# nrf9230_application register map
Vendor: Nordic Semiconductor; Series: nRF92; File version: 1
CPU: CM33 r0p4, little endian, MPU, FPU, 3 interrupt priority bits, 480 interrupts, 8 SAU regions
Registers are 32-bit, read-write, reset 0x0 unless marked. A register's access mark holds for its fields unless they carry their own. Offsets are from the block's base; [hi:lo] are bit positions; lines under a group give offsets from that group; {n}, {i} and the like mark numbered series.

## GLOBAL_FICR_NS — Factory Information Configuration Registers
Base 0x0FFFE000
0x00 SOCINFO group — Unspecified
  0x00 PARTNO ro reset 0xFFFFFFFF — Part number.
    [31:0] PART
  0x04 HWREVISION ro reset 0xFFFFFFFF — Hardware revision.
    [31:0] HWREVISION — Hardvare revision.
  0x08 PRODUCTIONREVISION ro reset 0xFFFFFFFF — Production reversion.
0x0C BLE group — Unspecified
  0x00 ADDRTYPE ro reset 0xFFFFFFFF — Device address type.
    [0] TYPE
      0=Public address; 1=Random address
  {0x4+4j} ADDR[{j}] (j=0..1) ro reset 0xFFFFFFFF — Description collection: 48 bit device address.
    [31:0] ADDR — Device address [n].
  {0xC+4j} ER[{j}] (j=0..3) ro reset 0xFFFFFFFF — Description collection: Encryption Root.
    [31:0] ER — Encryption root word [n].
  {0x1C+4j} IR[{j}] (j=0..3) ro reset 0xFFFFFFFF — Description collection: Identity Root.
    [31:0] IR — Identity root word [n].
0x50 INFO group — Device info
  0x00 CONFIGID ro reset 0xFFFFFFFF — Configuration identifier
    [15:0] HWID — Identification number for the HW
  0x04 PART ro reset 0xFFFFFFFF — Part code
    [31:0] PART
      0xFFFFFFFF=Unspecified
  0x08 VARIANT ro reset 0xFFFFFFFF — Part Variant, Hardware version and Production configuration
    [31:0] VARIANT — Part Variant, Hardware version and Production configuration, encoded as ASCII
      0xFFFFFFFF=Unspecified
  0x0C PACKAGE ro reset 0xFFFFFFFF — Package option
    [31:0] PACKAGE
      0xFFFFFFFF=Unspecified
  0x10 RAM ro reset 0xFFFFFFFF — RAM variant
    [31:0] RAM
      0xFFFFFFFF=Unspecified
  0x14 MRAM ro reset 0xFFFFFFFF — MRAM variant
    [31:0] MRAM
      0xFFFFFFFF=Unspecified
  0x18 CODEPAGESIZE ro reset 0x1000 — Code memory page size in bytes
    [31:0] CODEPAGESIZE
      0xFFFFFFFF=Unspecified
  0x1C CODESIZE ro reset 0x100 — Code memory size
    [31:0] CODESIZE — Code memory size in number of pages
      0xFFFFFFFF=Unspecified
  0x20 DEVICETYPE ro
    [31:0] DEVICETYPE
      0=Die (Device is an physical DIE); 0xFFFFFFFF=FPGA (Device is an FPGA)
0x80 SIPINFO group — SIP-specific device info
  0x00 PARTNO ro reset 0xFFFFFFFF — SIP part number
  {0x4+j} HWREVISION[{j}] (j=0..3) 8-bit ro reset 0xFF — Description collection: SIP hardware revision, encoded in ASCII, ex B0A or B1A
    [7:0] HWREVISION
  {0x8+j} VARIANT[{j}] (j=0..3) 8-bit ro reset 0xFF — Description collection: SIP VARIANT, encoded in ASCII, ex SIAA, SIBA or SICA
    [7:0] VARIANT
  0x0C PMICVERSION ro
    [31:0] PMICVERSION — PMIC version, incremental code
  {0x10+j} TESTSITE[{j}] (j=0..3) 8-bit ro — Description collection: Test site, in ascii
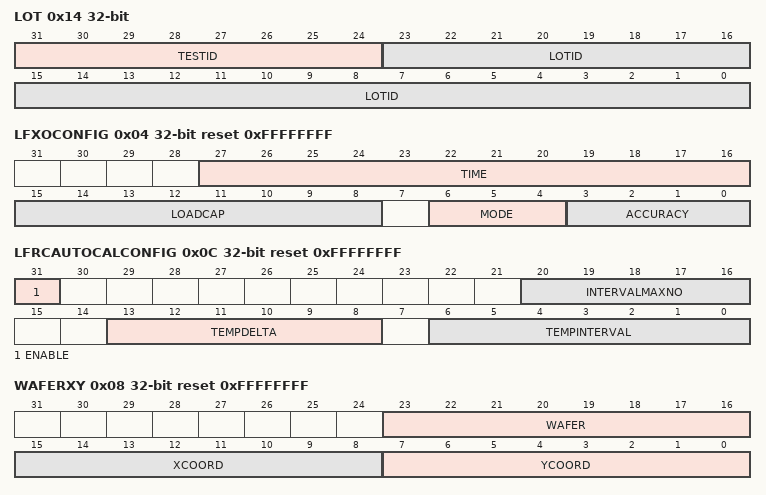
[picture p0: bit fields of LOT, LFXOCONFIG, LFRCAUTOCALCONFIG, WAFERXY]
  0x14 LOT ro — Lot number + test index in hex format (number digits 0-9).
    [31:24] TESTID — Test ID in hex format
    [23:0] LOTID — Lot number in hex format
  {0x18+j} TESTPROGRAMID[{j}] (j=0..3) 8-bit ro — Description collection: Test program id, in ascii
  0x1C OSATPARTNO ro reset 0xFFFFFFFF — OSAT part number
  {0x20+j} HWBUILDVERSION[{j}] (j=0..3) 8-bit ro reset 0xFF — Description collection: OSAT production build version
  0x24 OVERRIDE group — Unspecified
    0x00 LFOSC group — Unspecified
      0x00 CONFIG reset 0xFFFFFFFF — LF oscillator configuration. Note. This configuration overrides corresponding LF oscillator configuration in BICR when set.
        [3:0] SRC — LF oscillator source.
          15=Unconfigured (LF oscillator source is unconfigured. Default will be used.); 0=LFXO (Use LFXO as source for the LF oscillator.); 1=LFRC (Use LFRC as source for the LF oscillator.); 2=LFLPRC (Use LFLPRC as source for the LF oscillator.); 3=Synth (Use LF Synth as source for the LF oscillator.)
      0x04 LFXOCONFIG reset 0xFFFFFFFF — LFXO configuration. Note. This configuration overrides corresponding LFXO configuration in BICR when set.
        [27:16] TIME — LFXO startup time in ms.
          0xFFF=Unconfigured (Startup time has not been configured.)
        [15:8] LOADCAP — Built-in load capacitors selection in 1 pF steps. Max. value 25 pF.
          255=Unconfigured (The built-in load capacitors is unconfigured. LFXO will not start unless LOADCAP is configured.); 0=External (Do not use the built-in load capacitors, only external capacitors will be used.)
        [6:4] MODE — LFXO mode. LFXO will not start unless MODE is configured.
          7=Unconfigured (The mode is unconfigured.); 0=Pierce (LFXO Pierce mode.); 1=PIXO (LFXO PIXO mode.); 2=ExtSine (LFXO in external sine wave mode.); 3=ExtSquare (LFXO in external square wave mode.)
        [3:0] ACCURACY — LFXO crystal or external signal accuracy.
          15=Unconfigured (The accuracy is unconfigured.); 0=500ppm (LFXO crystal or external signal has an accuracy of 500 ppm.); 1=250ppm (LFXO crystal or external signal has an accuracy of 250 ppm.); 2=150ppm (LFXO crystal or external signal has an accuracy of 150 ppm.); 3=100ppm (LFXO crystal or external signal has an accuracy of 100 ppm.); 4=75ppm (LFXO crystal or external signal has an accuracy of 75 ppm.); 5=50ppm (LFXO crystal or external signal has an accuracy of 50 ppm.); 6=30ppm (LFXO crystal or external signal has an accuracy of 30 ppm.); 7=20ppm (LFXO crystal or external signal has an accuracy of 20 ppm.)
      0x08 LFXOCAL reset 0xFFFFFFFF — LFXO calibration needed. Must be written to 0xFFFFFFFF after any modification of the LFXO board circuit, load capacitance, or crystal swap. Note. This configuration overrides corresponding LFXO calibration in BICR when set.
        [31:0] LFXOCAL — LFXO calibration needed. Must be written to 0xFFFFFFFF after any modification of the LFXO board circuit, load capacitance, or crystal swap.
          0xFFFFFFFF=Calibrate the LFXO at startup
      0x0C LFRCAUTOCALCONFIG reset 0xFFFFFFFF — LFRC autocalibration configuration. Note. This configuration overrides corresponding LFRC autocalibration configuration in BICR when set.
        [31] ENABLE — LFRC.AUTOCALCONFIG register enable.
          0=Enabled (LFRC.AUTOCALCONFIG register has been configured and can be used.); 1=Disabled (LFRC.AUTOCALCONFIG register has not been configured and cannot be used.)
        [20:16] INTERVALMAXNO — Maximum number of TEMPINTERVAL periods in between calibrations, independent of temperature changes.
        [13:8] TEMPDELTA — Temperature delta that should trigger a calibration in 0.25 degrees steps.
        [6:0] TEMPINTERVAL — Temperature measurement interval in 0.25 s steps.
    0x10 HFXO64M group — Unspecified
      0x00 CONFIG reset 0xFFFFFFFF — HFXO64M configuration. Note. This configuration overrides corresponding XO configuration in BICR when set.
        [2:0] MODE — HFXO64M mode.
          7=Unconfigured (The mode is unconfigured.); 0=Normal operating mode; 1=TCXO (TCXO/bypass mode); {v}=Crystal{v} (Reserved value) (v=2..6)
      0x04 STARTUPTIME reset 0xFFFFFFFF — HFXO64M startup time in us. Note. This configuration overrides corresponding XO configuration in BICR when set.
        [31:0] TIME — HFXO64M startup time in us.
          0xFFFFFFFF=Unconfigured (Startup time has not been configured.)
0xC0 PRODTEST group — Unspecified
  0x00 CP group — Unspecified
    {0x0+4k} LOTNR[{k}] (k=0..1) ro reset 0xFFFFFFFF — Description collection: Lot number.
      [31:0] LOTNR — Lot number
    0x08 WAFERXY ro reset 0xFFFFFFFF — Wafer number and die X,Y coordinate.
      [23:16] WAFER — Wafer number
      [15:8] XCOORD — Die x coordinate
      [7:0] YCOORD — Die y coordinate
    0x0C PROGVERSION1 ro reset 0xFFFFFFFF — CP1 test program version.
      [31:0] VAL — CP1 test program version
    0x10 PROGVERSION2 ro reset 0xFFFFFFFF — CP2 test program version.
      [31:0] VAL — CP2 test program version
    0x14 PASSID1 ro reset 0xFFFFFFFF — CP1 pass ID.
      [31:0] VAL
    0x18 PASSID2 ro reset 0xFFFFFFFF — CP2 pass ID.
      [31:0] VAL
    0x1C TIMESTAMP1 ro reset 0xFFFFFFFF — Timestamp for when CP1 starts or ends (YYYYMMDDTHHMMSS)
      [31:0] VAL — CP1 timestamp
    0x20 TIMESTAMP2 ro reset 0xFFFFFFFF — Timestamp for when CP2 starts or ends (YYYYMMDDTHHMMSS)
      [31:0] VAL — CP2 timestamp
  0x24 FT group — Unspecified
    0x00 PROGVERSION1 ro reset 0xFFFFFFFF — FT1 test program version.
      [31:0] PROGVERSION1 — FT1 test program version
    0x04 PROGVERSION2 ro reset 0xFFFFFFFF — FT2/EQA test program version.
      [31:0] PROGVERSION2 — FT2/EQA test program version
    0x08 PASSID1 ro reset 0xFFFFFFFF — FT1 pass ID.
      [31:0] VAL
    0x0C PASSID2 ro reset 0xFFFFFFFF — FT2/EQA pass ID.
      [31:0] VAL
    0x10 TIMESTAMP1 ro reset 0xFFFFFFFF — Timestamp for when FT1 starts or ends (YYYYMMDDTHHMMSS)
      [31:0] VAL — FT1 timestamp
    0x14 TIMESTAMP2 ro reset 0xFFFFFFFF — Timestamp for when FT2/EQA starts or ends (YYYYMMDDTHHMMSS)
      [31:0] VAL — FT2/EQA timestamp
0x100 TRIM group — Unspecified
  0x00 SYSCTRL group — Unspecified
    0x00 FLL16M group — Unspecified
      0x00 CONFIG group — Unspecified
        0x00 CFGCKSW16M ro reset 0xFFFFFFFF — Config value for SYSCTRL.FLL16M.CONFIG.CFGCKSW16M
          [31:0] VALUE — Config value
      0x04 TRIM group — Unspecified
        0x00 RCOARSE ro reset 0xFFFFFFFF — Trim value for SYSCTRL.FLL16M.TRIM.RCOARSE
          [31:0] VALUE — Trim value
        0x04 RFINE ro reset 0xFFFFFFFF — Trim value for SYSCTRL.FLL16M.TRIM.RFINE
          [31:0] VALUE — Trim value
        0x08 VSUP ro reset 0xFFFFFFFF — Trim value for SYSCTRL.FLL16M.TRIM.VSUP
          [31:0] VALUE — Trim value
        0x0C CKSW16MTRIM ro reset 0xFFFFFFFF — Trim value for SYSCTRL.FLL16M.TRIM.CKSW16MTRIM
          [31:0] VALUE — Trim value
        0x10 TCOEF ro reset 0xFFFFFFFF — Trim value for SYSCTRL.FLL16M.TRIM.TCOEF
          [31:0] VALUE — Trim value
    0x18 LFRC group — Unspecified
      0x00 CAL group — Unspecified
        0x00 LFRCOSCTRIM ro reset 0xFFFFFFFF — Trim value for SYSCTRL.LFRC.CAL.LFRCOSCTRIM
          [31:0] VALUE — Trim value
    0x1C LFXO group — Unspecified
      0x00 TRIM group — Unspecified
        0x00 PDLOWERTHR ro reset 0xFFFFFFFF — Trim value for SYSCTRL.LFXO.TRIM.PDLOWERTHR
          [31:0] VALUE — Trim value
        0x04 PDUPPERTHR ro reset 0xFFFFFFFF — Trim value for SYSCTRL.LFXO.TRIM.PDUPPERTHR
          [31:0] VALUE — Trim value
        0x08 BIAS ro reset 0xFFFFFFFF — Trim value for SYSCTRL.LFXO.TRIM.BIAS
          [31:0] VALUE — Trim value
        0x0C PIXO ro reset 0xFFFFFFFF — Trim value for SYSCTRL.LFXO.TRIM.PIXO
          [31:0] VALUE — Trim value
        0x10 TRIMBUS ro reset 0xFFFFFFFF — Trim value for SYSCTRL.LFXO.TRIM.TRIMBUS
          [31:0] VALUE — Trim value
    0x30 HFXO64M group — Unspecified
      0x00 TRIM group — Unspecified
        0x00 DOUBLERCOMP ro reset 0xFFFFFFFF — Trim value for SYSCTRL.HFXO64M.TRIM.DOUBLERCOMP
          [31:0] VALUE — Trim value
        0x04 CHIRPTUNE ro reset 0xFFFFFFFF — Trim value for SYSCTRL.HFXO64M.TRIM.CHIRPTUNE
          [31:0] VALUE — Trim value
        0x08 RTUNE ro reset 0xFFFFFFFF — Trim value for SYSCTRL.HFXO64M.TRIM.RTUNE
          [31:0] VALUE — Trim value
    0x3C LFLPRC group — Unspecified
      0x00 VSUP ro reset 0xFFFFFFFF — Trim value for SYSCTRL.LFLPRC.TRIM.VSUP
        [31:0] VALUE — Trim value
      0x04 RCOARSE ro reset 0xFFFFFFFF — Trim value for SYSCTRL.LFLPRC.TRIM.RCOARSE
        [31:0] VALUE — Trim value
      0x08 RFINE ro reset 0xFFFFFFFF — Trim value for SYSCTRL.LFLPRC.TRIM.RFINE
        [31:0] VALUE — Trim value
      0x0C PWMFINE ro reset 0xFFFFFFFF — Trim value for SYSCTRL.LFLPRC.TRIM.PWMFINE
        [31:0] VALUE — Trim value
    0x74 AUDIOPLL group — Unspecified
      0x00 TRIM group — Unspecified
        0x00 CTUNE ro reset 0xFFFFFFFF — Trim value for SYSCTRL.AUDIOPLL.TRIM.CTUNE
          [31:0] VALUE — Trim value
    0x78 AUDIOPLLPM group — Unspecified
      0x00 TRIM group — Unspecified
        0x00 VREFPM ro reset 0xFFFFFFFF — Trim value for SYSCTRL.AUDIOPLLPM.TRIM.VREFPM
          [31:0] VALUE — Trim value
    0x7C USBHSPLL group — Unspecified
      0x00 TRIM group — Unspecified
        0x00 CTUNE ro reset 0xFFFFFFFF — Trim value for SYSCTRL.USBHSPLL.TRIM.CTUNE
          [31:0] VALUE — Trim value
    0x80 MBIAS group — Unspecified
      0x00 CONFIG group — Unspecified
        0x00 CFG ro reset 0xFFFFFFFF — Config value for SYSCTRL.MBIAS.CONFIG.CFG
          [31:0] VALUE — Trim value
      0x04 TRIM group — Unspecified
        0x00 MBIASIBPP ro reset 0xFFFFFFFF — Trim value for SYSCTRL.MBIAS.TRIM.MBIASIBPP
          [31:0] VALUE — Trim value
        0x04 MBIASIBPSR ro reset 0xFFFFFFFF — Trim value for SYSCTRL.MBIAS.TRIM.MBIASIBPSR
          [31:0] VALUE — Trim value
    0x8C OSCRFR group — Unspecified
      0x00 TRIM group — Unspecified
        0x00 OSC ro reset 0xFFFFFFFF — Trim value for SYSCTRL.OSCRFR.TRIM.OSC
          [31:0] VALUE — Trim value
        0x04 IBPSR ro reset 0xFFFFFFFF — Trim value for SYSCTRL.OSCRFR.TRIM.IBPSR
          [31:0] VALUE — Trim value
    0x104 VREGMRAM130 group — Unspecified
      0x00 TRIM group — Unspecified
        0x00 VBG ro reset 0xFFFFFFFF — Trim value for SYSCTRL.VREGMRAM130.TRIM.VBG
          [31:0] VALUE — Trim value
        0x04 BIAS ro reset 0xFFFFFFFF — Trim value for SYSCTRL.VREGMRAM130.TRIM.BIAS
          [31:0] VALUE — Trim value
        0x08 VPR ro reset 0xFFFFFFFF — Trim value for SYSCTRL.VREGMRAM130.TRIM.VPR
          [31:0] VALUE — Trim value
        0x0C VREF ro reset 0xFFFFFFFF — Trim value for SYSCTRL.VREGMRAM130.TRIM.VREF
          [31:0] VALUE — Trim value
    0x114 VREGMRAM131 group — Unspecified
      0x00 TRIM group — Unspecified
        0x00 VBG ro reset 0xFFFFFFFF — Trim value for SYSCTRL.VREGMRAM131.TRIM.VBG
          [31:0] VALUE — Trim value
        0x04 BIAS ro reset 0xFFFFFFFF — Trim value for SYSCTRL.VREGMRAM131.TRIM.BIAS
          [31:0] VALUE — Trim value
        0x08 VPR ro reset 0xFFFFFFFF — Trim value for SYSCTRL.VREGMRAM131.TRIM.VPR
          [31:0] VALUE — Trim value
        0x0C VREF ro reset 0xFFFFFFFF — Trim value for SYSCTRL.VREGMRAM131.TRIM.VREF
          [31:0] VALUE — Trim value
    0x134 VREGUSB group — Unspecified
      0x00 TRIM group — Unspecified
        0x00 TRIMVDD ro reset 0xFFFFFFFF — Trim value for SYSCTRL.VREGUSB.TRIM.TRIMVDD
          [31:0] VALUE — Trim value
        0x04 TRIMIBP ro reset 0xFFFFFFFF — Trim value for SYSCTRL.VREGUSB.TRIM.TRIMIBP
          [31:0] VALUE — Trim value
        0x08 TRIM0V8 ro reset 0xFFFFFFFF — Trim value for SYSCTRL.VREGUSB.TRIM.TRIM0V8
          [31:0] VALUE — Trim value
        0x0C TRIM3V3 ro reset 0xFFFFFFFF — Trim value for SYSCTRL.VREGUSB.TRIM.TRIM3V3
          [31:0] VALUE — Trim value
    0x144 VDETAO0V8 group — Unspecified
      0x00 TRIM group — Unspecified
        0x00 BROWNOUT ro reset 0xFFFFFFFF — Trim value for SYSCTRL.VDETAO0V8.TRIM.BROWNOUT
          [31:0] VALUE — Trim value
        0x04 PWRGOOD ro reset 0xFFFFFFFF — Trim value for SYSCTRL.VDETAO0V8.TRIM.PWRGOOD
          [31:0] VALUE — Trim value
      0x08 CONFIG group — Unspecified
        0x00 BROWNOUTHP ro reset 0xFFFFFFFF — Config value for SYSCTRL.VDETAO0V8.CONFIG.BROWNOUTHP
          [31:0] VALUE — Config value
    0x150 VDETAO1V8 group — Unspecified
      0x00 TRIM group — Unspecified
        0x00 BROWNOUTLVLHIGH ro reset 0xFFFFFFFF — Trim value for SYSCTRL.VDETAO1V8.TRIM.BROWNOUTLVLHIGH
          [31:0] VALUE — Trim value
        0x04 BROWNOUTLVLLOW ro reset 0xFFFFFFFF — Trim value for SYSCTRL.VDETAO1V8.TRIM.BROWNOUTLVLLOW
          [31:0] VALUE — Trim value
    0x158 VDETVS0V8 group — Unspecified
      0x00 TRIM group — Unspecified
        0x00 BROWNOUT ro reset 0xFFFFFFFF — Trim value for SYSCTRL.VDETVS0V8.TRIM.BROWNOUT
          [31:0] VALUE — Trim value
        0x04 PWRGOOD ro reset 0xFFFFFFFF — Trim value for SYSCTRL.VDETVS0V8.TRIM.PWRGOOD
          [31:0] VALUE — Trim value
    0x164 VDET1V0 group — Unspecified
      0x00 TRIM group — Unspecified
        0x00 PWRGOOD ro reset 0xFFFFFFFF — Trim value for SYSCTRL.VDET1V0.TRIM.PWRGOOD
          [31:0] VALUE — Trim value
    0x168 HSFLL120 group — Unspecified
      0x00 TRIM group — Unspecified
        0x00 VSUP ro reset 0xFFFFFFFF — Trim value for SYSCTRL.HSFLL120.TRIM.VSUP
          [31:0] VALUE — Trim value
        {0x4+4m} COARSE[{m}] (m=0..5) ro reset 0xFFFFFFFF — Description collection: Trim value for SYSCTRL.HSFLL120.TRIM.COARSE
          [31:0] VALUE — Trim value
        {0x1C+4m} FINE[{m}] (m=0..5) ro reset 0xFFFFFFFF — Description collection: Trim value for SYSCTRL.HSFLL120.TRIM.FINE
          [31:0] VALUE — Trim value
        0x34 TCOEF ro reset 0xFFFFFFFF — Trim value for SYSCTRL.HSFLL120.TRIM.TCOEF
          [31:0] VALUE — Trim value
    0x1A0 HSFLL121 group — Unspecified
      0x00 TRIM group — Unspecified
        0x00 VSUP ro reset 0xFFFFFFFF — Trim value for SYSCTRL.HSFLL121.TRIM.VSUP
          [31:0] VALUE — Trim value
        {0x4+4m} COARSE[{m}] (m=0..5) ro reset 0xFFFFFFFF — Description collection: Trim value for SYSCTRL.HSFLL121.TRIM.COARSE
          [31:0] VALUE — Trim value
        {0x1C+4m} FINE[{m}] (m=0..5) ro reset 0xFFFFFFFF — Description collection: Trim value for SYSCTRL.HSFLL121.TRIM.FINE
          [31:0] VALUE — Trim value
        0x34 TCOEF ro reset 0xFFFFFFFF — Trim value for SYSCTRL.HSFLL121.TRIM.TCOEF
          [31:0] VALUE — Trim value
    0x210 MEMCONF120 group — Unspecified
      {0x0+4l} REPAIR[{l}] (l=0..18) group — Unspecified
        0x00 BITLINE ro reset 0xFFFFFFFF — Description cluster: Trim value for SYSCTRL.MEMCONF120.REPAIR[n].BITLINE
          [31:0] VALUE — Trim value
      {0x4C+4l} BLOCKTYPE[{l}] (l=0..7) group — Unspecified
        0x00 TRIM ro reset 0xFFFFFFFF — Description cluster: Trim value for SYSCTRL.MEMCONF120.BLOCKTYPE[n].TRIM
          [31:0] VALUE — Trim value
    0x27C MEMCONF130 group — Unspecified
      {0x0+4l} BLOCKTYPE[{l}] (l=0..2) group — Unspecified
        0x00 TRIM ro reset 0xFFFFFFFF — Description cluster: Trim value for SYSCTRL.MEMCONF130.BLOCKTYPE[n].TRIM
          [31:0] VALUE — Trim value
  0x288 GLOBAL group — Unspecified
    0x00 SAADC group — Unspecified
      {0x0+4l} CAL[{l}] (l=0..2) ro reset 0xFFFFFFFF — Description collection: Trim value for GLOBAL.SAADC.CAL
        [31:0] VALUE — Trim value
      0x0C CALREF ro reset 0xFFFFFFFF — Trim value for GLOBAL.SAADC.CALREF
        [31:0] VALUE — Trim value
      {0x10+4l} LINCALCOEFF[{l}] (l=0..5) ro reset 0xFFFFFFFF — Description collection: Trim value for GLOBAL.SAADC.TRIM.LINCALCOEFF
        [31:0] VALUE — Trim value
    0x28 TEMP group — Unspecified
      0x00 CALIB ro reset 0xFFFFFFFF — Trim value for GLOBAL.TEMP.CALIB
        [31:0] VALUE — Trim value
    0x30 CANPLL group — Unspecified
      0x00 TRIM group — Unspecified
        0x00 CTUNE ro reset 0xFFFFFFFF — Trim value for GLOBAL.CANPLL.TRIM.CTUNE
          [31:0] VALUE — Trim value
    0x34 CANPLLPM group — Unspecified
      0x00 TRIM group — Unspecified
        0x00 VREFPM ro reset 0xFFFFFFFF — Trim value for GLOBAL.CANPLLPM.TRIM.VREFPM
          [31:0] VALUE — Trim value
    0x38 COMP group — Unspecified
      0x00 REFTRIM ro reset 0xFFFFFFFF — Trim value for GLOBAL.COMP.REFTRIM
        [31:0] VALUE — Trim value
      0x04 RCALTRIM ro reset 0xFFFFFFFF — Trim value for GLOBAL.COMP.DFT.RCALTRIM
        [31:0] VALUE — Trim value
  0x2C8 APPLICATION group — Unspecified
    0x00 HSFLL group — Unspecified
      0x00 TRIM group — Unspecified
        0x00 VSUP ro reset 0xFFFFFFFF — Trim value for APPLICATION.HSFLL.TRIM.VSUP
          [31:0] VALUE — Trim value
        {0x4+4m} COARSE[{m}] (m=0..5) ro reset 0xFFFFFFFF — Description collection: Trim value for APPLICATION.HSFLL.TRIM.COARSE
          [31:0] VALUE — Trim value
        {0x1C+4m} FINE[{m}] (m=0..5) ro reset 0xFFFFFFFF — Description collection: Trim value for APPLICATION.HSFLL.TRIM.FINE
          [31:0] VALUE — Trim value
        0x34 TCOEF ro reset 0xFFFFFFFF — Trim value for APPLICATION.HSFLL.TRIM.TCOEF
          [31:0] VALUE — Trim value
    0x38 MEMCONF group — Unspecified
      {0x0+4l} BLOCKTYPE[{l}] (l=0..3) group — Unspecified
        0x00 TRIM ro reset 0xFFFFFFFF — Description cluster: Trim value for APPLICATION.MEMCONF.BLOCKTYPE[n].TRIM
          [31:0] VALUE — Trim value
  0x310 RADIOCORE group — Unspecified
    0x00 HSFLL group — Unspecified
      0x00 TRIM group — Unspecified
        0x00 VSUP ro reset 0xFFFFFFFF — Trim value for RADIOCORE.HSFLL.TRIM.VSUP
          [31:0] VALUE — Trim value
        {0x4+4m} COARSE[{m}] (m=0..5) ro reset 0xFFFFFFFF — Description collection: Trim value for RADIOCORE.HSFLL.TRIM.COARSE
          [31:0] VALUE — Trim value
        {0x1C+4m} FINE[{m}] (m=0..5) ro reset 0xFFFFFFFF — Description collection: Trim value for RADIOCORE.HSFLL.TRIM.FINE
          [31:0] VALUE — Trim value
        0x34 TCOEF ro reset 0xFFFFFFFF — Trim value for RADIOCORE.HSFLL.TRIM.TCOEF
          [31:0] VALUE — Trim value
    0x38 MEMCONF group — Unspecified
      {0x0+4l} BLOCKTYPE[{l}] (l=0..3) group — Unspecified
        0x00 TRIM ro reset 0xFFFFFFFF — Description cluster: Trim value for RADIOCORE.MEMCONF.BLOCKTYPE[n].TRIM
          [31:0] VALUE — Trim value
    0x48 RADIO group — Unspecified
      0x00 SPHYNXANA group — Unspecified
        {0x0+4m} FSCTRL{m} ro reset 0xFFFFFFFF (m=0..2) — Trim value for RADIOCORE.RADIO.SPHYNXANA.FSCTRL{m}
          [31:0] VALUE — Trim value
        0x0C RXCTRL ro reset 0xFFFFFFFF — Trim value for RADIOCORE.RADIO.SPHYNXANA.RXCTRL
          [31:0] VALUE — Trim value
        0x10 OVRRXTRIMCODE ro reset 0xFFFFFFFF — Trim value for RADIOCORE.RADIO.SPHYNXANA.OVRRXTRIMCODE
          [31:0] VALUE — Trim value
      0x14 RXAGC group — Unspecified
        0x00 CALIBRATION ro reset 0xFFFFFFFF — RADIOCORE.RADIO.RXAGC.CALIBRATION
          [31:0] VALUE — Trim value
      0x18 PVTTOT ro reset 0xFFFFFFFF — Trim value for RADIOCORE.RADIO.PVTTOT
        [31:0] VALUE — Trim value
      0x1C KDTC ro reset 0xFFFFFFFF — Trim value for RADIOCORE.RADIO.KDTC
        [31:0] VALUE — Trim value
      0x20 TXHFGAIN ro reset 0xFFFFFFFF — Trim value for RADIOCORE.RADIO.TXHFGAIN
        [31:0] VALUE — Trim value
      0x24 PVTTOFIX ro reset 0xFFFFFFFF — Trim value for RADIOCORE.RADIO.PVTTOFIX
        [31:0] VALUE — Trim value
      0x28 LOOPGAIN ro reset 0xFFFFFFFF — Trim value for RADIOCORE.RADIO.ADPLLTRIMCOMMAND0
        [31:0] VALUE — Trim value
  0x3CC BOOT group — Unspecified
    0x00 GPIO group — Unspecified
      0x00 PORTCNF group — Unspecified
        0x00 DRIVECTRL group — Unspecified
          {0x0+4p} P[{p}] (p=0..1) ro reset 0xFFFFFFFF — Description collection: Trim value for GPIO.Pn.PORTCNF.DRIVECTRL
            [31:0] VALUE — Trim value
    0x10 HSFLL120 group — Unspecified
      0x00 TRIM group — Unspecified
        0x00 VSUP ro reset 0xFFFFFFFF — Trim value for SYSCTRL.HSFLL120.TRIM.VSUP
          [31:0] VALUE — Trim value
        0x04 COARSE ro reset 0xFFFFFFFF — Trim value for SYSCTRL.HSFLL120.TRIM.COARSE
          [31:0] VALUE — Trim value
        0x08 FINE ro reset 0xFFFFFFFF — Trim value for SYSCTRL.HSFLL120.TRIM.FINE
          [31:0] VALUE — Trim value
        0x0C TCOEF ro reset 0xFFFFFFFF — Trim value for SYSCTRL.HSFLL120.TRIM.TCOEF
          [31:0] VALUE — Trim value
    0x20 OTPC group — Unspecified
      0x00 WAITSTATES ro reset 0xFFFFFFFF — Config value for GLOBAL.OTPC.WAITSTATES
      0x04 FREQUENCY ro reset 0xFFFFFFFF — Config value for GLOBAL.OTPC.FREQUENCY
        [31:0] FREQUENCY — Frequency in MHz
  0x3F4 COMMON group — Unspecified
    0x00 FFFF ro reset 0xFFFFFFFF — Value to be written to multibit MIRROR register in MMIs (MIRROR=1)
      [31:0] FFFF — Mirror register value
    0x04 ZERO ro reset 0xFFFFFFFF — Value to be written to MIRROR register in MMIs (MIRROR=0)
      [31:0] ZERO — Mirror register value
    0x08 ONE ro reset 0xFFFFFFFF — Value to be written to MIRROR register in MMIs (MIRROR=1)
      [31:0] ONE — Mirror register value
  0x400 SECURE group — Unspecified
    0x00 HSFLL group — Unspecified
      0x00 TRIM group — Unspecified
        0x00 VSUP ro reset 0xFFFFFFFF — Trim value for SECURE.HSFLL.TRIM.VSUP
          [31:0] VALUE — Trim value
        {0x4+4m} COARSE[{m}] (m=0..5) ro reset 0xFFFFFFFF — Description collection: Trim value for SECURE.HSFLL.TRIM.COARSE
          [31:0] VALUE — Trim value
        {0x1C+4m} FINE[{m}] (m=0..5) ro reset 0xFFFFFFFF — Description collection: Trim value for SECURE.HSFLL.TRIM.FINE
          [31:0] VALUE — Trim value
    0x34 HSFLL200 group — Unspecified
      0x00 TRIM group — Unspecified
        0x00 VSUP ro reset 0xFFFFFFFF — Trim value for SECURE.HSFLL200.TRIM.VSUP
          [31:0] VALUE — Trim value
        {0x4+4m} COARSE[{m}] (m=0..3) ro reset 0xFFFFFFFF — Description collection: Trim value for SECURE.HSFLL200.TRIM.COARSE
          [31:0] VALUE — Trim value
        {0x14+4m} FINE[{m}] (m=0..3) ro reset 0xFFFFFFFF — Description collection: Trim value for SECURE.HSFLL200.TRIM.FINE
          [31:0] VALUE — Trim value
    0x58 MEMCONF group — Unspecified
      {0x0+4l} BLOCKTYPE[{l}] (l=0..7) group — Unspecified
        0x00 TRIM ro reset 0xFFFFFFFF — Description cluster: Trim value for SECURE.MEMCONF.BLOCKTYPE[n].TRIM
          [31:0] VALUE — Trim value
    0x78 MEMCONF200 group — Unspecified
      0x00 BLOCKTYPE group — Unspecified
        0x00 TRIM ro reset 0xFFFFFFFF — Trim value for SECURE.MEMCONF200.BLOCKTYPE.TRIM
          [31:0] VALUE — Trim value
    0x7C TCOEFS group — Unspecified
      0x00 TRIM group — Unspecified
        0x00 HSFLL ro reset 0xFFFFFFFF — Trim value for SECURE.HSFLL.TRIM.TCOEF
          [31:0] VALUE — Trim value
        0x04 HSFLL200 ro reset 0xFFFFFFFF — Trim value for SECURE.HSFLL200.TRIM.TCOEF
          [31:0] VALUE — Trim value
  0x500 CELLCORE group — Unspecified
    0x00 HSFLL group — Unspecified
      0x00 TRIM group — Unspecified
        0x00 VSUP ro reset 0xFFFFFFFF — Trim value for CELLCORE.HSFLL.TRIM.VSUP
          [31:0] VALUE — Trim value
        0x04 COARSE ro reset 0xFFFFFFFF — Trim value for CELLCORE.HSFLL.TRIM.COARSE
          [31:0] VALUE — Trim value
        0x08 FINE ro reset 0xFFFFFFFF — Trim value for CELLCORE.HSFLL.TRIM.FINE
          [31:0] VALUE — Trim value
        0x0C TCOEF ro reset 0xFFFFFFFF — Trim value for CELLCORE.HSFLL.TRIM.TCOEF
          [31:0] VALUE — Trim value
    0x10 MEMCONF group — Unspecified
      {0x0+4l} BLOCKTYPE[{l}] (l=0..3) group — Unspecified
        0x00 TRIM ro reset 0xFFFFFFFF — Description cluster: Trim value for CELLCORE.MEMCONF.BLOCKTYPE[n].TRIM
          [31:0] VALUE — Trim value
    0x20 MCPLL group — Unspecified
      0x00 RTUNE ro reset 0xFFFFFFFF — Trim value for CELLCORE.MCPLL.RTUNE
        [31:0] VALUE — Trim value
  0x524 CELLDSP group — Unspecified
    0x00 HSFLL group — Unspecified
      0x00 TRIM group — Unspecified
        0x00 VSUP ro reset 0xFFFFFFFF — Trim value for CELLDSP.HSFLL.TRIM.VSUP
          [31:0] VALUE — Trim value
        {0x4+4m} COARSE[{m}] (m=0..4) ro reset 0xFFFFFFFF — Description collection: Trim value for CELLDSP.HSFLL.TRIM.COARSE
          [31:0] VALUE — Trim value
        {0x18+4m} FINE[{m}] (m=0..4) ro reset 0xFFFFFFFF — Description collection: Trim value for CELLDSP.HSFLL.TRIM.FINE
          [31:0] VALUE — Trim value
        0x2C TCOEF ro reset 0xFFFFFFFF — Trim value for CELLDSP.HSFLL.TRIM.TCOEF
          [31:0] VALUE — Trim value
    0x30 MEMCONF group — Unspecified
      {0x0+4l} REPAIR[{l}] (l=0..11) group — Unspecified
        0x00 BITLINE ro reset 0xFFFFFFFF — Description cluster: Trim value for CELLDSP.MEMCONF.REPAIR[n].BITLINE
          [31:0] VALUE — Trim value
      {0x30+4l} BLOCKTYPE[{l}] (l=0..8) group — Unspecified
        0x00 TRIM ro reset 0xFFFFFFFF — Description cluster: Trim value for CELLDSP.MEMCONF.BLOCKTYPE[n].TRIM
          [31:0] VALUE — Trim value
  0x5A8 CELLRF group — Unspecified
    0x00 HSFLL group — Unspecified
      0x00 TRIM group — Unspecified
        0x00 VSUP ro reset 0xFFFFFFFF — Trim value for CELLRF.HSFLL.TRIM.VSUP
          [31:0] VALUE — Trim value
        0x04 COARSE ro reset 0xFFFFFFFF — Trim value for CELLRF.HSFLL.TRIM.COARSE
          [31:0] VALUE — Trim value
        0x08 FINE ro reset 0xFFFFFFFF — Trim value for CELLRF.HSFLL.TRIM.FINE
          [31:0] VALUE — Trim value
        0x0C TCOEF ro reset 0xFFFFFFFF — Trim value for CELLRF.HSFLL.TRIM.TCOEF
          [31:0] VALUE — Trim value
    0x10 MEMCONF group — Unspecified
      {0x0+4l} REPAIR[{l}] (l=0..6) group — Unspecified
        0x00 BITLINE ro reset 0xFFFFFFFF — Description cluster: Trim value for CELLRF.MEMCONF.REPAIR[n].BITLINE
          [31:0] VALUE — Trim value
      {0x1C+4l} BLOCKTYPE[{l}] (l=0..2) group — Unspecified
        0x00 TRIM ro reset 0xFFFFFFFF — Description cluster: Trim value for CELLRF.MEMCONF.BLOCKTYPE[n].TRIM
          [31:0] VALUE — Trim value
    0x38 TXDFE group — Unspecified
      0x00 TX_R_TRIM ro reset 0xFFFFFFFF — Trim value for CELLRF.TXDFE.TX_R_TRIM
        [31:0] VALUE — Trim value
      0x04 TX_CALIB ro reset 0xFFFFFFFF — Trim value for CELLRF.TXDFE.TX_CALIB
        [31:0] VALUE — Trim value
      0x08 TX_IQ_COMP ro reset 0xFFFFFFFF — Trim value for CELLRF.TXDFE.TX_IQ_COMP
        [31:0] VALUE — Trim value
      0x0C TX_IQ_COMP_B13 ro reset 0xFFFFFFFF — Trim value for CELLRF.TXDFE.TX_IQ_COMP for BAND13
        [31:0] VALUE — Trim value
      {0x10+4l} TX_DC_COMP[{l}] (l=0..5) ro reset 0xFFFFFFFF — Description collection: Trim values for CELLRF.TXDFE.TX_DC_COMP (4db, 2DB, 0DB, N1DB, N3DB, N6DB)
        [31:0] VALUE — Trim value
      {0x28+4l} TX_DC_COMP_B13[{l}] (l=0..5) ro reset 0xFFFFFFFF — Description collection: Trim values for CELLRF.TXDFE.ID for BAND13. (4db, 2DB, 0DB, N1DB, N3DB, N6DB)
        [31:0] VALUE — Trim value
      {0x40+4l} TX_ABB_DCCOMP[{l}] (l=0..5) ro reset 0xFFFFFFFF — Description collection: Trim values for CELLRF.TXDFE.TX_ABB_DCCOMP (4db, 2DB, 0DB, N1DB, N3DB, N6DB)
        [31:0] VALUE — Trim value
      {0x58+4l} TX_ABB_DCCOMP_B13[{l}] (l=0..5) ro reset 0xFFFFFFFF — Description collection: Trim values for CELLRF.TXDFE.TX_ABB_DCCOMP for BAND13. (4db, 2DB, 0DB, N1DB, N3DB, N6DB)
        [31:0] VALUE — Trim value
      0x70 TX_TMEAS ro reset 0xFFFFFFFF — Trim value for CELLRF.TXDFE.TX_TMEAS
        [31:0] VALUE — Trim value
      {0x74+4l} TRIMSPARE[{l}] (l=0..3) ro reset 0xFFFFFFFF — Description collection: Trim value for CELLRF.TXDFE.TRIMSPARE[n]
        [31:0] VALUE — Trim value
    0xBC RXDFE group — Unspecified
      0x00 RX_R_TRIM ro reset 0xFFFFFFFF — Trim value for CELLRF.RXDFE.RX_R_TRIM
        [31:0] VALUE — Trim value
      0x04 RX_RC_TRIM ro reset 0xFFFFFFFF — Trim value for CELLRF.RXDFE.RX_RC_TRIM
        [31:0] VALUE — Trim value
      {0x8+4l} TRIMSPARE[{l}] (l=0..3) ro reset 0xFFFFFFFF — Description collection: Trim value for CELLRF.RXDFE.TRIMSPARE
        [31:0] VALUE — Trim value
    0xD4 RFPLL group — Unspecified
      0x00 SX_R_TRIM reset 0xFFFFFFFF — Trim value for CELLRF.RFPLL.SX_R_TRIM
        [31:0] VALUE — Trim value
      0x04 SX_DLLCTRL1_B11 reset 0xFFFFFFFF — Trim value for CELLRF.RFPLL.SX_DLLCTRL1. BPF_TRIM for BAND11.
        [31:0] VALUE — Trim value
      0x08 SX_DLLCTRL1_B2 reset 0xFFFFFFFF — Trim value for CELLRF.RFPLL.SX_DLLCTRL1. BPF_TRIM for BAND11.
        [31:0] VALUE — Trim value
      0x0C SX_DLLCTRL1_B41 reset 0xFFFFFFFF — Trim value for CELLRF.RFPLL.SX_DLLCTRL1 BPF_TRIM for BAND41.
        [31:0] VALUE — Trim value
      0x10 SX_LDOCTRL ro reset 0xFFFFFFFF — Trim value for CELLRF.RFPLL.SX_LDO_CTRL
        [31:0] VALUE — Trim value
      {0x14+4l} TRIMSPARE[{l}] (l=0..3) ro reset 0xFFFFFFFF — Description collection: Trim value for CELLRF.RFPLL.TRIMSPARE[n]
        [31:0] VALUE — Trim value
    0xF8 SENSORADC group — Unspecified
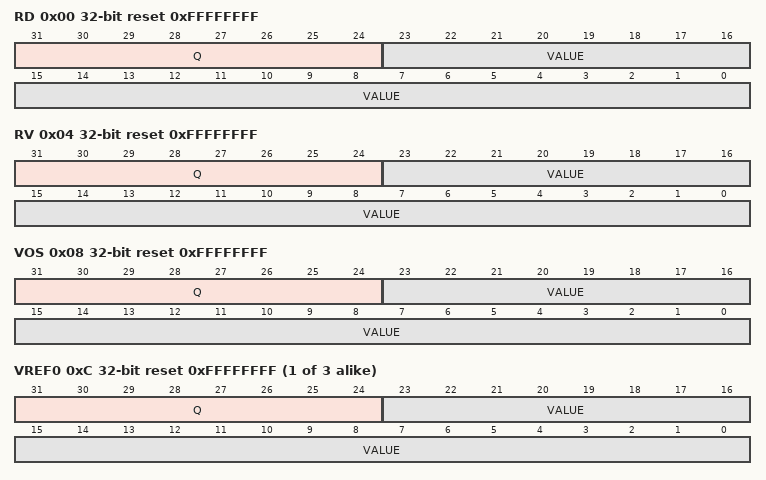
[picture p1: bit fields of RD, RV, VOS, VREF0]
      0x00 RD ro reset 0xFFFFFFFF — Trim value for CELLRF.SENSORADC.RD
        [31:24] Q — Q Value
        [23:0] VALUE — Value (Scaled with refclk (122.88 MHz))
      0x04 RV ro reset 0xFFFFFFFF — Trim value for CELLRF.SENSORADC.RV
        [31:24] Q — Q Value
        [23:0] VALUE — Value (refclk / RV (122.88 MHz / 8.0 MHz))
      0x08 VOS ro reset 0xFFFFFFFF — Trim value for CELLRF.SENSORADC.VOS
        [31:24] Q — Q Value
        [23:0] VALUE
      {0xC+4l} VREF{l} ro reset 0xFFFFFFFF (l=0..2) — Trim value for CELLRF.SENSORADC.VREF{l}
        [31:24] Q — Q Value
        [23:0] VALUE
      0x18 ICTRL ro reset 0xFFFFFFFF — Trim value for CELLRF.SENSORADC.ICTRL
        [31:0] VALUE — Trim value
      0x1C INTD25C ro reset 0xFFFFFFFF — Trim value for CELLRF.SENSORADC.INTD25C
        [31:0] VALUE — Trim value
      {0x20+4l} TRIMSPARE[{l}] (l=0..3) ro reset 0xFFFFFFFF — Description collection: Trim value for CELLRF.RFPLL.TRIMSPARE[n]
        [31:0] VALUE — Trim value
    0x128 COMMONTRIM group — Unspecified
      0x00 TX group — Unspecified
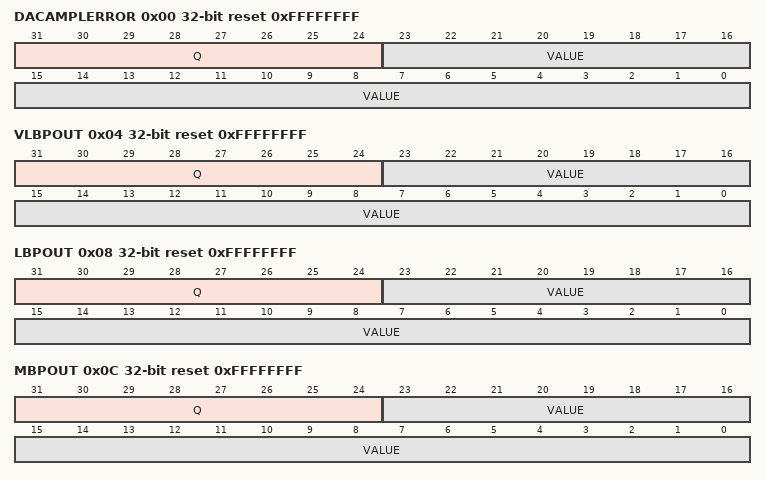
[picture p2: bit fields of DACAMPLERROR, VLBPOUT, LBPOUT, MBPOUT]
        0x00 DACAMPLERROR ro reset 0xFFFFFFFF — Trim value for CELLRF.COMMONTRIM.TX.DACAMPLERROR
          [31:24] Q — Q Value
          [23:0] VALUE
        0x04 VLBPOUT ro reset 0xFFFFFFFF — Trim value for CELLRF.COMMONTRIM.TX.VLBPOUT
          [31:24] Q — Q Value
          [23:0] VALUE
        0x08 LBPOUT ro reset 0xFFFFFFFF — Trim value for CELLRF.COMMONTRIM.TX.LBPOUT
          [31:24] Q — Q Value
          [23:0] VALUE
        0x0C MBPOUT ro reset 0xFFFFFFFF — Trim value for CELLRF.COMMONTRIM.TX.MBPOUT
          [31:24] Q — Q Value
          [23:0] VALUE
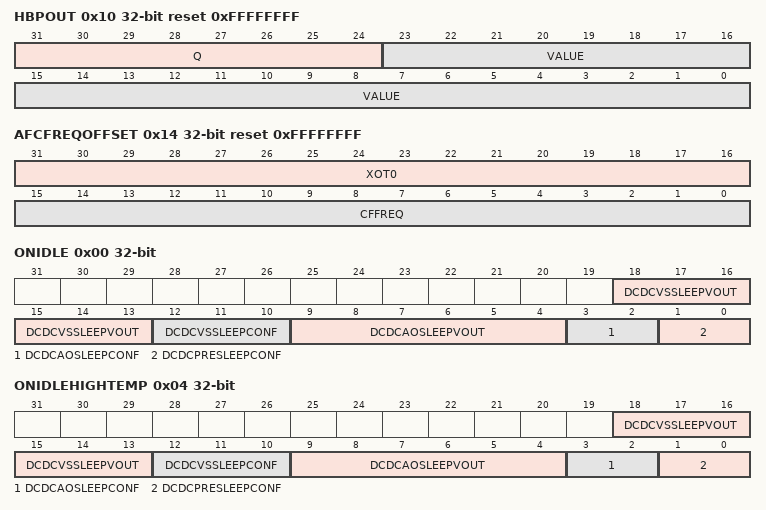
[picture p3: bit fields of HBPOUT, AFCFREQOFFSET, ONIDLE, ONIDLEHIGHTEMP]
        0x10 HBPOUT ro reset 0xFFFFFFFF — Trim value for CELLRF.COMMONTRIM.TX.HBPOUT
          [31:24] Q — Q Value
          [23:0] VALUE
        0x14 AFCFREQOFFSET ro reset 0xFFFFFFFF — Trim value for CELLRF.COMMONTRIM.AFCFREQOFFSET.
          [31:16] XOT0 — Calibration temperature in Q8.
          [15:0] CFFREQ — Frequency offset in Q30 format.
  0x6E8 ISIMCORE group — Unspecified
    0x00 HSFLL group — Unspecified
      0x00 TRIM group — Unspecified
        0x00 VSUP ro reset 0xFFFFFFFF — Trim value for ISIMCORE.HSFLL.TRIM.VSUP
          [31:0] VALUE — Trim value
        0x04 COARSE ro reset 0xFFFFFFFF — Trim value for ISIMCORE.HSFLL.TRIM.COARSE
          [31:0] VALUE — Trim value
        0x08 FINE ro reset 0xFFFFFFFF — Trim value for ISIMCORE.HSFLL.TRIM.FINE
          [31:0] VALUE — Trim value
        0x0C TCOEF ro reset 0xFFFFFFFF — Trim value for ISIMCORE.HSFLL.TRIM.TCOEF
          [31:0] VALUE — Trim value
0x900 PMIC group — Unspecified
  0x00 SLEEPMODE group — Unspecified
    0x00 ONIDLE — PMIC DCDC sleep modes during SYSTEM ON IDLE
      [18:13] DCDCVSSLEEPVOUT — Configuration for PMIC DCDCVSSLEEPVOUT register.
        25=default (DCDC_VS 0.8V)
      [12:10] DCDCVSSLEEPCONF — Configuration for PMIC DCDCVSSLEEPCONF register.
        6=default (DCDC_VS ON, Imax 1mA)
      [9:4] DCDCAOSLEEPVOUT — Configuration for PMIC DCDCAOSLEEPVOUT register.
        25=default (DCDC_AO 0.8V)
      [3:2] DCDCAOSLEEPCONF — Configuration for PMIC DCDCAOSLEEPCONF register.
        2=default (DCDC_AO ON, Imax 1mA)
      [1:0] DCDCPRESLEEPCONF — Configuration for PMIC DCDCPRESLEEPCONF register.
        2=default (DCDC_PRE ON, 1.8V, Imax 1mA)
    0x04 ONIDLEHIGHTEMP — PMIC DCDC sleep modes during SYSTEM ON IDLE on high temperature (>105C)
      [18:13] DCDCVSSLEEPVOUT — Configuration for PMIC DCDCVSSLEEPVOUT register.
        25=default (DCDC_VS 0.8V)
      [12:10] DCDCVSSLEEPCONF — Configuration for PMIC DCDCVSSLEEPCONF register.
        4=default (DCDC_VS ON, Imax 50mA)
      [9:4] DCDCAOSLEEPVOUT — Configuration for PMIC DCDCAOSLEEPVOUT register.
        25=default (DCDC_AO 0.8V)
      [3:2] DCDCAOSLEEPCONF — Configuration for PMIC DCDCAOSLEEPCONF register.
        0=default (DCDC_AO ON, Imax 50mA)
      [1:0] DCDCPRESLEEPCONF — Configuration for PMIC DCDCPRESLEEPCONF register.
        0=default (DCDC_PRE ON, 1.8V, Imax 50mA)
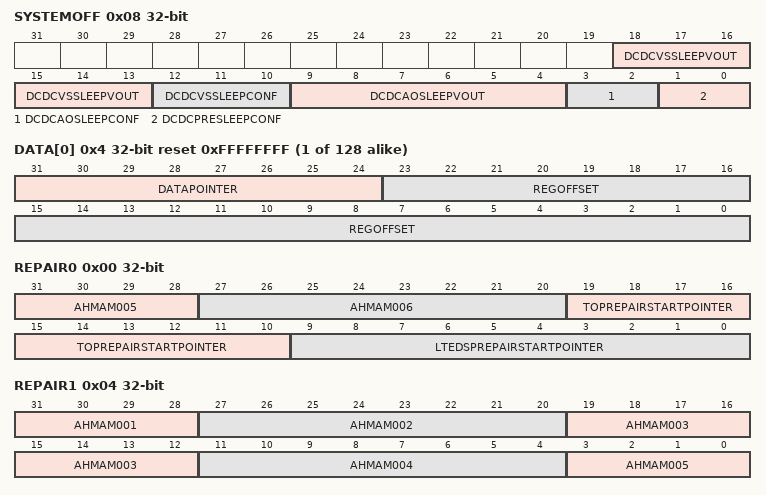
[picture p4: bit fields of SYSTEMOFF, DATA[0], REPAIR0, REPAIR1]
    0x08 SYSTEMOFF — PMIC DCDC sleep modes during SYSTEM OFF
      [18:13] DCDCVSSLEEPVOUT — Configuration for PMIC DCDCVSSLEEPVOUT register.
        25=default (DCDC_VS 0.8V)
      [12:10] DCDCVSSLEEPCONF — Configuration for PMIC DCDCVSSLEEPCONF register.
        2=default (DCDC_VS OFF)
      [9:4] DCDCAOSLEEPVOUT — Configuration for PMIC DCDCAOSLEEPVOUT register.
        15=default (DCDC_AO 0.65V)
      [3:2] DCDCAOSLEEPCONF — Configuration for PMIC DCDCAOSLEEPCONF register.
        2=default (DCDC_AO ON, Imax 1mA)
      [1:0] DCDCPRESLEEPCONF — Configuration for PMIC DCDCPRESLEEPCONF register.
        2=default (DCDC_PRE ON, 1.8V, Imax 1mA)
0x9A0 BOOT group — Unspecified
  0x00 SIZE ro reset 0xFFFFFFFF — Size of DATA group
    [31:0] VALUE — Number of trim values stored in DATA.
  {0x4+4j} DATA[{j}] (j=0..127) ro reset 0xFFFFFFFF — Description collection: Compressed address and data pointer.
    [31:24] DATAPOINTER — Pointer to location in TRIM group
    [23:0] REGOFFSET — Address offset to trim register
0xBB0 SRAM group — Unspecified
  0x00 REPAIR0 — SRAM repair register 0
    [31:28] AHMAM005 — AhmaRf M0RAM Ram 5 bits 4:7
    [27:20] AHMAM006 — AhmaRf M0RAM Ram 6
    [19:10] TOPREPAIRSTARTPOINTER — Top repair data start pointer
    [9:0] LTEDSPREPAIRSTARTPOINTER — LteDsp repair data start pointer
  0x04 REPAIR1 — SRAM repair register 1
    [31:28] AHMAM001 — AhmaRf M0RAM Ram 1 bits 4:7
    [27:20] AHMAM002 — AhmaRf M0RAM Ram 2
    [19:12] AHMAM003 — AhmaRf M0RAM Ram 3
    [11:4] AHMAM004 — AhmaRf M0RAM Ram 4
    [3:0] AHMAM005 — AhmaRf M0RAM Ram 5 bits 0:3
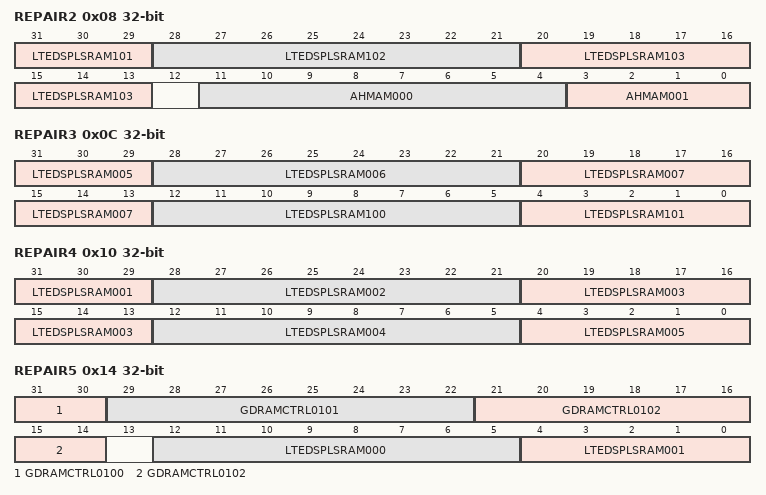
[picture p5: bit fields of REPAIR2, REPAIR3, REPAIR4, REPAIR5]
  0x08 REPAIR2 — SRAM repair register 2
    [31:29] LTEDSPLSRAM101 — LteDsp LS_RAM1 Ram 1 bits 5:7
    [28:21] LTEDSPLSRAM102 — LteDsp LS_RAM1 Ram 2
    [20:13] LTEDSPLSRAM103 — LteDsp LS_RAM1 Ram 3
    [11:4] AHMAM000 — AhmaRf M0RAM Ram 0
    [3:0] AHMAM001 — AhmaRf M0RAM Ram 1 bits 0:3
  0x0C REPAIR3 — SRAM repair register 3
    [31:29] LTEDSPLSRAM005 — LteDsp LS_RAM0 Ram 5 bits 5:7
    [28:21] LTEDSPLSRAM006 — LteDsp LS_RAM0 Ram 6
    [20:13] LTEDSPLSRAM007 — LteDsp LS_RAM0 Ram 7
    [12:5] LTEDSPLSRAM100 — LteDsp LS_RAM1 Ram 0
    [4:0] LTEDSPLSRAM101 — LteDsp LS_RAM1 Ram 1 bits 0:4
  0x10 REPAIR4 — SRAM repair register 4
    [31:29] LTEDSPLSRAM001 — LteDsp LS_RAM0 Ram 1 bits 5:7
    [28:21] LTEDSPLSRAM002 — LteDsp LS_RAM0 Ram 2
    [20:13] LTEDSPLSRAM003 — LteDsp LS_RAM0 Ram 3
    [12:5] LTEDSPLSRAM004 — LteDsp LS_RAM0 Ram 4
    [4:0] LTEDSPLSRAM005 — LteDsp LS_RAM0 Ram 5 bits 0:4
  0x14 REPAIR5 — SRAM repair register 5
    [31:30] GDRAMCTRL0100 — GD RAMC_01 Ram 0 bits 6:7
    [29:22] GDRAMCTRL0101 — GD RAMC_01 Ram 1
    [21:14] GDRAMCTRL0102 — GD RAMC_01 Ram 2
    [12:5] LTEDSPLSRAM000 — LteDsp LS_RAM0 Ram 0
    [4:0] LTEDSPLSRAM001 — LteDsp LS_RAM0 Ram 1 bits 0:4
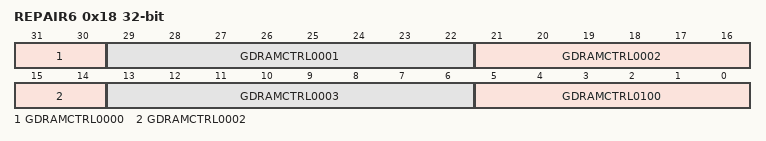
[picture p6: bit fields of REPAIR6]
  0x18 REPAIR6 — SRAM repair register 6
    [31:30] GDRAMCTRL0000 — GD RAMC_00 Ram 0 bits 6:7
    [29:22] GDRAMCTRL0001 — GD RAMC_00 Ram 1
    [21:14] GDRAMCTRL0002 — GD RAMC_00 Ram 2
    [13:6] GDRAMCTRL0003 — GD RAMC_00 Ram 3
    [5:0] GDRAMCTRL0100 — GD RAMC_01 Ram 0 bits 0:5
  0x1C REPAIR7 — SRAM repair register 7
    [5:0] GDRAMCTRL0000 — GD RAMC_00 Ram 0 bits 0:5
0xBFC CRC32 — CRC32 value for FICR (except this word)
  [31:0] VALUE — CRC32 value

## Notices in the file
Copyright (c) 2010 - 2024, Nordic Semiconductor ASA
All rights reserved.
Redistribution and use in source and binary forms, with or without modification,
are permitted provided that the following conditions are met:
1. Redistributions of source code must retain the above copyright notice, this
list of conditions and the following disclaimer.
2. Redistributions in binary form, except as embedded into a Nordic
Semiconductor ASA integrated circuit in a product or a software update for
such product, must reproduce the above copyright notice, this list of
conditions and the following disclaimer in the documentation and/or other
materials provided with the distribution.
3. Neither the name of Nordic Semiconductor ASA nor the names of its
contributors may be used to endorse or promote products derived from this
software without specific prior written permission.
4. This software, with or without modification, must only be used with a
Nordic Semiconductor ASA integrated circuit.
5. Any software provided in binary form under this license must not be reverse
engineered, decompiled, modified and/or disassembled.
THIS SOFTWARE IS PROVIDED BY NORDIC SEMICONDUCTOR ASA "AS IS" AND ANY EXPRESS
OR IMPLIED WARRANTIES, INCLUDING, BUT NOT LIMITED TO, THE IMPLIED WARRANTIES
OF MERCHANTABILITY, NONINFRINGEMENT, AND FITNESS FOR A PARTICULAR PURPOSE ARE
DISCLAIMED. IN NO EVENT SHALL NORDIC SEMICONDUCTOR ASA OR CONTRIBUTORS BE
LIABLE FOR ANY DIRECT, INDIRECT, INCIDENTAL, SPECIAL, EXEMPLARY, OR
CONSEQUENTIAL DAMAGES (INCLUDING, BUT NOT LIMITED TO, PROCUREMENT OF SUBSTITUTE
GOODS OR SERVICES; LOSS OF USE, DATA, OR PROFITS; OR BUSINESS INTERRUPTION)
HOWEVER CAUSED AND ON ANY THEORY OF LIABILITY, WHETHER IN CONTRACT, STRICT
LIABILITY, OR TORT (INCLUDING NEGLIGENCE OR OTHERWISE) ARISING IN ANY WAY OUT
OF THE USE OF THIS SOFTWARE, EVEN IF ADVISED OF THE POSSIBILITY OF SUCH DAMAGE.
